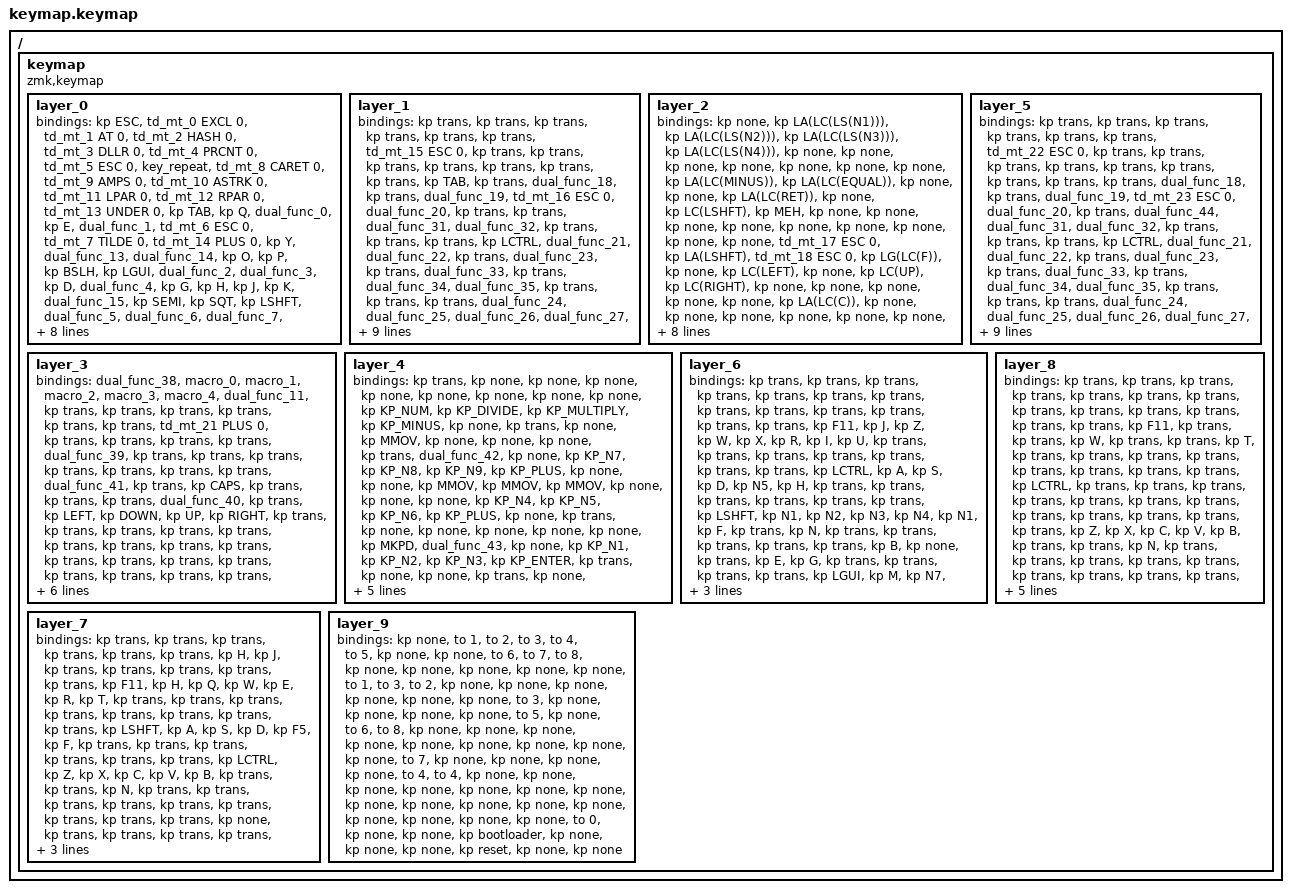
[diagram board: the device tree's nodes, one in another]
// Auto-generated by qmk_to_zmk.py - Complete keymap conversion
#include <behaviors.dtsi>
#include <dt-bindings/zmk/keys.h>

/ {
    keymap {
        compatible = "zmk,keymap";

        layer_0 {
            bindings = <
                &kp ESC &td_mt_0 EXCL 0 &td_mt_1 AT 0 &td_mt_2 HASH 0 &td_mt_3 DLLR 0 &td_mt_4 PRCNT 0 &td_mt_5 ESC 0 &key_repeat &td_mt_8 CARET 0 &td_mt_9 AMPS 0 &td_mt_10 ASTRK 0 &td_mt_11 LPAR 0 &td_mt_12 RPAR 0 &td_mt_13 UNDER 0 &kp TAB &kp Q &dual_func_0 &kp E &dual_func_1 &td_mt_6 ESC 0 &td_mt_7 TILDE 0 &td_mt_14 PLUS 0 &kp Y &dual_func_13 &dual_func_14 &kp O &kp P &kp BSLH &kp LGUI &dual_func_2 &dual_func_3 &kp D &dual_func_4 &kp G &kp H &kp J &kp K &dual_func_15 &kp SEMI &kp SQT &kp LSHFT &dual_func_5 &dual_func_6 &dual_func_7 &dual_func_8 &dual_func_9 &dual_func_10 &dual_func_16 &dual_func_17 &kp M &kp COMMA &kp DOT &kp FSLH &kp RSHFT &kp LG(LC(SPACE)) &kp LCTRL &kp trans &kp LALT &kp LGUI &kp LEFT &kp DOWN &kp UP &kp RIGHT &kp none &dual_func_11 &dual_func_12 &to 9 &tog 4 &kp END &kp PG_UP &kp BSPC &lt 2 DEL &kp HOME &kp PG_DN &lt 3 RET &kp SPACE
            >;
        };

        layer_1 {
            bindings = <
                &kp trans &kp trans &kp trans &kp trans &kp trans &kp trans &td_mt_15 ESC 0 &kp trans &kp trans &kp trans &kp trans &kp trans &kp trans &kp trans &kp TAB &kp trans &dual_func_18 &kp trans &dual_func_19 &td_mt_16 ESC 0 &dual_func_20 &kp trans &kp trans &dual_func_31 &dual_func_32 &kp trans &kp trans &kp trans &kp LCTRL &dual_func_21 &dual_func_22 &kp trans &dual_func_23 &kp trans &dual_func_33 &kp trans &dual_func_34 &dual_func_35 &kp trans &kp trans &kp trans &dual_func_24 &dual_func_25 &dual_func_26 &dual_func_27 &dual_func_28 &kp trans &kp trans &dual_func_36 &kp trans &kp trans &kp trans &kp trans &kp trans &kp LG(DOT) &kp LCTRL &kp LGUI &kp LALT &kp none &kp trans &kp trans &kp trans &kp trans &kp trans &dual_func_29 &dual_func_30 &dual_func_37 &kp trans &kp trans &kp trans &kp trans &kp trans &kp trans &kp trans &kp trans &kp trans
            >;
        };

        layer_2 {
            bindings = <
                &kp none &kp LA(LC(LS(N1))) &kp LA(LC(LS(N2))) &kp LA(LC(LS(N3))) &kp LA(LC(LS(N4))) &kp none &kp none &kp none &kp none &kp none &kp none &kp none &kp LA(LC(MINUS)) &kp LA(LC(EQUAL)) &kp none &kp none &kp LA(LC(RET)) &kp none &kp LC(LSHFT) &kp MEH &kp none &kp none &kp none &kp none &kp none &kp none &kp none &kp none &kp none &td_mt_17 ESC 0 &kp LA(LSHFT) &td_mt_18 ESC 0 &kp LG(LC(F)) &kp none &kp LC(LEFT) &kp none &kp LC(UP) &kp LC(RIGHT) &kp none &kp none &kp none &kp none &kp none &kp LA(LC(C)) &kp none &kp none &kp none &kp none &kp none &kp none &kp none &kp none &kp none &kp none &kp none &kp none &kp none &kp none &kp none &td_mt_19 ESC 0 &kp none &kp LA(LC(RET)) &td_mt_20 ESC 0 &kp none &kp none &kp none &dual_func_37 &kp trans &kp none &kp LA(LC(EQUAL)) &kp none &kp trans &kp none &kp LA(LC(MINUS)) &kp LA(LC(RET)) &kp none
            >;
        };

        layer_3 {
            bindings = <
                &dual_func_38 &macro_0 &macro_1 &macro_2 &macro_3 &macro_4 &dual_func_11 &kp trans &kp trans &kp trans &kp trans &kp trans &kp trans &td_mt_21 PLUS 0 &kp trans &kp trans &kp trans &kp trans &dual_func_39 &kp trans &kp trans &kp trans &kp trans &kp trans &kp trans &kp trans &dual_func_41 &kp trans &kp CAPS &kp trans &kp trans &kp trans &dual_func_40 &kp trans &kp LEFT &kp DOWN &kp UP &kp RIGHT &kp trans &kp trans &kp trans &kp trans &kp trans &kp trans &kp trans &kp trans &kp trans &kp trans &kp trans &kp trans &kp trans &kp trans &kp trans &kp trans &kp trans &kp trans &kp trans &kp trans &kp trans &kp trans &kp trans &kp trans &kp trans &kp none &kp trans &kp trans &dual_func_37 &kp trans &kp trans &kp trans &kp LA(BSPC) &kp trans &kp trans &kp trans &kp trans &kp trans
            >;
        };

        layer_4 {
            bindings = <
                &kp trans &kp none &kp none &kp none &kp none &kp none &kp none &kp none &kp none &kp KP_NUM &kp KP_DIVIDE &kp KP_MULTIPLY &kp KP_MINUS &kp none &kp trans &kp none &kp MMOV &kp none &kp none &kp none &kp trans &dual_func_42 &kp none &kp KP_N7 &kp KP_N8 &kp KP_N9 &kp KP_PLUS &kp none &kp none &kp MMOV &kp MMOV &kp MMOV &kp none &kp none &kp none &kp KP_N4 &kp KP_N5 &kp KP_N6 &kp KP_PLUS &kp none &kp trans &kp none &kp none &kp none &kp none &kp none &kp MKPD &dual_func_43 &kp none &kp KP_N1 &kp KP_N2 &kp KP_N3 &kp KP_ENTER &kp trans &kp none &kp none &kp trans &kp none &kp MKPD &kp KP_N0 &kp KP_N0 &kp KP_DOT &kp KP_ENTER &kp trans &kp MKPD &kp none &dual_func_37 &kp trans &kp MWHL &kp none &kp trans &kp trans &kp MWHL &kp none &kp trans &kp trans
            >;
        };

        layer_5 {
            bindings = <
                &kp trans &kp trans &kp trans &kp trans &kp trans &kp trans &td_mt_22 ESC 0 &kp trans &kp trans &kp trans &kp trans &kp trans &kp trans &kp trans &kp trans &kp trans &dual_func_18 &kp trans &dual_func_19 &td_mt_23 ESC 0 &dual_func_20 &kp trans &dual_func_44 &dual_func_31 &dual_func_32 &kp trans &kp trans &kp trans &kp LCTRL &dual_func_21 &dual_func_22 &kp trans &dual_func_23 &kp trans &dual_func_33 &kp trans &dual_func_34 &dual_func_35 &kp trans &kp trans &kp trans &dual_func_24 &dual_func_25 &dual_func_26 &dual_func_27 &dual_func_28 &kp trans &kp trans &dual_func_36 &kp trans &kp trans &kp trans &kp trans &kp trans &kp LG(DOT) &kp trans &kp LGUI &kp trans &kp SPACE &kp trans &kp trans &kp trans &kp trans &kp trans &dual_func_29 &dual_func_30 &dual_func_37 &kp trans &kp trans &kp trans &kp trans &kp trans &kp trans &kp trans &kp trans &kp trans
            >;
        };

        layer_6 {
            bindings = <
                &kp trans &kp trans &kp trans &kp trans &kp trans &kp trans &kp trans &kp trans &kp trans &kp trans &kp trans &kp trans &kp trans &kp F11 &kp J &kp Z &kp W &kp X &kp R &kp I &kp U &kp trans &kp trans &kp trans &kp trans &kp trans &kp trans &kp trans &kp LCTRL &kp A &kp S &kp D &kp N5 &kp H &kp trans &kp trans &kp trans &kp trans &kp trans &kp trans &kp LSHFT &kp N1 &kp N2 &kp N3 &kp N4 &kp N1 &kp F &kp trans &kp N &kp trans &kp trans &kp trans &kp trans &kp trans &kp B &kp none &kp trans &kp E &kp G &kp trans &kp trans &kp trans &kp trans &kp LGUI &kp M &kp N7 &dual_func_37 &kp LGUI &kp N7 &kp trans &kp SPACE &kp U &kp EQUAL &kp LA(LC(SEMI)) &kp trans &kp trans
            >;
        };

        layer_7 {
            bindings = <
                &kp trans &kp trans &kp trans &kp trans &kp trans &kp trans &kp H &kp J &kp trans &kp trans &kp trans &kp trans &kp trans &kp F11 &kp H &kp Q &kp W &kp E &kp R &kp T &kp trans &kp trans &kp trans &kp trans &kp trans &kp trans &kp trans &kp trans &kp LSHFT &kp A &kp S &kp D &kp F5 &kp F &kp trans &kp trans &kp trans &kp trans &kp trans &kp trans &kp LCTRL &kp Z &kp X &kp C &kp V &kp B &kp trans &kp trans &kp N &kp trans &kp trans &kp trans &kp trans &kp trans &kp trans &kp trans &kp trans &kp trans &kp none &kp trans &kp trans &kp trans &kp trans &kp LGUI &kp trans &kp trans &dual_func_37 &kp LGUI &kp trans &kp trans &kp SPACE &kp J &kp trans &kp trans &kp trans &kp trans
            >;
        };

        layer_8 {
            bindings = <
                &kp trans &kp trans &kp trans &kp trans &kp trans &kp trans &kp trans &kp trans &kp trans &kp trans &kp trans &kp trans &kp trans &kp F11 &kp trans &kp trans &kp W &kp trans &kp trans &kp T &kp trans &kp trans &kp trans &kp trans &kp trans &kp trans &kp trans &kp trans &kp LCTRL &kp trans &kp trans &kp trans &kp trans &kp trans &kp trans &kp trans &kp trans &kp trans &kp trans &kp trans &kp trans &kp Z &kp X &kp C &kp V &kp B &kp trans &kp trans &kp N &kp trans &kp trans &kp trans &kp trans &kp trans &kp trans &kp trans &kp trans &kp trans &kp none &kp trans &kp trans &kp trans &kp trans &kp LGUI &kp M &kp trans &dual_func_37 &kp LGUI &kp trans &kp trans &kp SPACE &kp trans &kp trans &kp trans &kp trans &kp trans
            >;
        };

        layer_9 {
            bindings = <
                &kp none &to 1 &to 2 &to 3 &to 4 &to 5 &kp none &kp none &to 6 &to 7 &to 8 &kp none &kp none &kp none &kp none &kp none &to 1 &to 3 &to 2 &kp none &kp none &kp none &kp none &kp none &kp none &to 3 &kp none &kp none &kp none &kp none &to 5 &kp none &to 6 &to 8 &kp none &kp none &kp none &kp none &kp none &kp none &kp none &kp none &kp none &to 7 &kp none &kp none &kp none &kp none &to 4 &to 4 &kp none &kp none &kp none &kp none &kp none &kp none &kp none &kp none &kp none &kp none &kp none &kp none &kp none &kp none &kp none &kp none &to 0 &kp none &kp none &kp bootloader &kp none &kp none &kp none &kp reset &kp none &kp none
            >;
        };

    };
};
